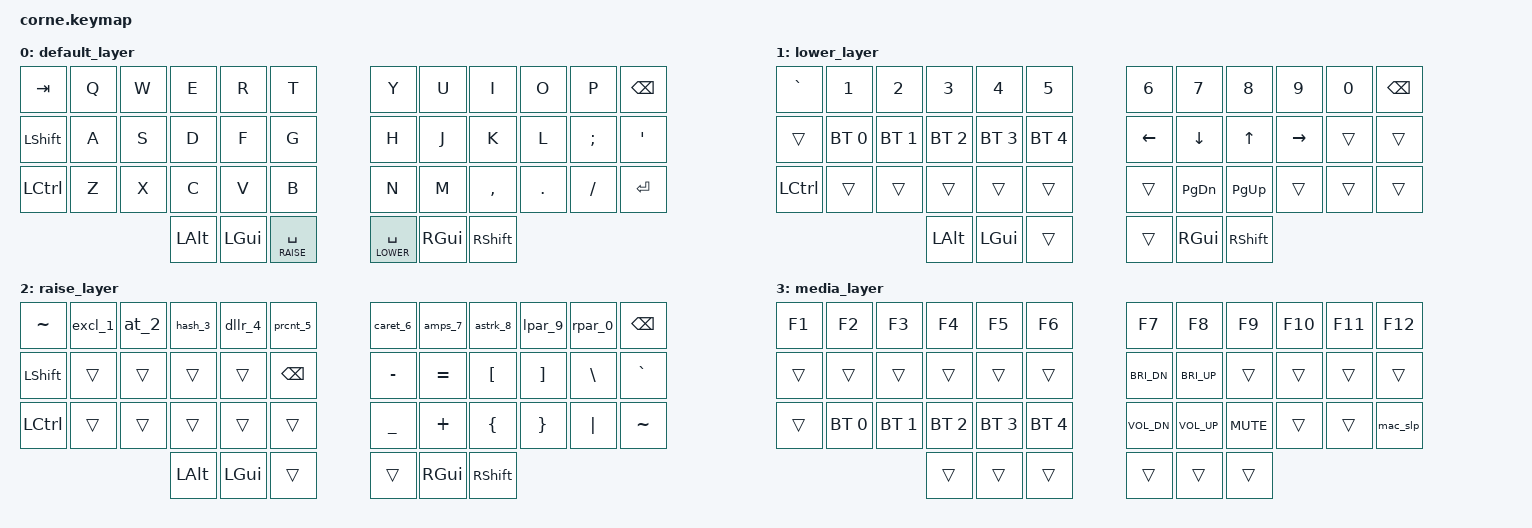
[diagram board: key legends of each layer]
/*
 * Copyright (c) 2020 The ZMK Contributors
 *
 * SPDX-License-Identifier: MIT
 */

#include <behaviors.dtsi>
#include <dt-bindings/zmk/keys.h>
#include <dt-bindings/zmk/bt.h>

// Mapping for different layers
#define DEFAULT 0
#define LOWER   1
#define RAISE   2
#define MEDIA   3


&lt {
    tapping-term-ms = <150>;
};

/ {
    macros {
        mac_slp: mac_slp {
        compatible = "zmk,behavior-macro-two-param";
        #binding-cells = <2>;
        wait-ms = <30>;
        tap-ms = <40>;
        bindings = <&macro_press &kp LCTRL &kp LGUI>
                 , <&macro_tap &kp Q &kp ESC>
                 , <&macro_release &kp LCTRL &kp LGUI>
                 ;
        };
    };
};

/ {
    behaviors {
        excl_1: EXCLAMATION_1 {
            compatible = "zmk,behavior-mod-morph";
            #binding-cells = <0>;
            bindings = <&kp EXCL>, <&kp N1>;
            mods = <(MOD_LSFT|MOD_RSFT)>;
        };
        at_2: AT_2 {
            compatible = "zmk,behavior-mod-morph";
            #binding-cells = <0>;
            bindings = <&kp AT>, <&kp N2>;
            mods = <(MOD_LSFT|MOD_RSFT)>;
        };
        hash_3: HASH_3 {
            compatible = "zmk,behavior-mod-morph";
            #binding-cells = <0>;
            bindings = <&kp HASH>, <&kp N3>;
            mods = <(MOD_LSFT|MOD_RSFT)>;
        };
        dllr_4: DOLLAR_4 {
            compatible = "zmk,behavior-mod-morph";
            #binding-cells = <0>;
            bindings = <&kp DLLR>, <&kp N4>;
            mods = <(MOD_LSFT|MOD_RSFT)>;
        };
        prcnt_5: PERCENT_5 {
            compatible = "zmk,behavior-mod-morph";
            #binding-cells = <0>;
            bindings = <&kp PRCNT>, <&kp N5>;
            mods = <(MOD_LSFT|MOD_RSFT)>;
        };
        caret_6: CARET_6 {
            compatible = "zmk,behavior-mod-morph";
            #binding-cells = <0>;
            bindings = <&kp CARET>, <&kp N6>;
            mods = <(MOD_LSFT|MOD_RSFT)>;
        };
        amps_7: AMPS_7 {
            compatible = "zmk,behavior-mod-morph";
            #binding-cells = <0>;
            bindings = <&kp AMPS>, <&kp N7>;
            mods = <(MOD_LSFT|MOD_RSFT)>;
        };
        astrk_8: ASTRK_7 {
            compatible = "zmk,behavior-mod-morph";
            #binding-cells = <0>;
            bindings = <&kp ASTRK>, <&kp N8>;
            mods = <(MOD_LSFT|MOD_RSFT)>;
        };
        lpar_9: LPAR_9 {
            compatible = "zmk,behavior-mod-morph";
            #binding-cells = <0>;
            bindings = <&kp LPAR>, <&kp N9>;
            mods = <(MOD_LSFT|MOD_RSFT)>;
        };
        rpar_0: RPAR_0 {
            compatible = "zmk,behavior-mod-morph";
            #binding-cells = <0>;
            bindings = <&kp RPAR>, <&kp N0>;
            mods = <(MOD_LSFT|MOD_RSFT)>;
        };
    };
};

/ {
    combos {
        compatible = "zmk,combos";
        combo_esc {
            timeout-ms = <50>;
            key-positions = <0 1>;
            bindings = <&kp ESC>;
        };
        combo_del {
            timeout-ms = <50>;
            key-positions = <10 11>;
            bindings = <&kp DEL>;
        };
        combo_caps {
            timeout-ms = <50>;
            key-positions = <0 1 2>;
            bindings = <&kp CAPS>;
            layers = <0 1 2>;
        };
        combo_media_BT_CLR {
            timeout-ms = <50>;
            key-positions = <0 1 2>;
            bindings = <&bt BT_CLR>;
            layers = <3>;
        };
    };
};

/ {      
    conditional_layers {
        compatible = "zmk,conditional-layers";
        tri_layer {
            if-layers = <1 2>;
            then-layer = <3>;
        };
    };
};


/ {
        keymap {
                compatible = "zmk,keymap";

                default_layer {
// -----------------------------------------------------------------------------------------
// | TAB  |  Q  |  W  |  E  |  R  |  T  |   |  Y  |  U  |  I  |  O  |  P  | BKSP |
// | SHFT |  A  |  S  |  D  |  F  |  G  |   |  H  |  J  |  K  |  L  |  ;  |  '   |
// | CTRL |  Z  |  X  |  C  |  V  |  B  |   |  N  |  M  |  ,  |  .  |  /  | ENT  |
//                    | ALT | GUI | SPC |   | SPC | GUI | SHFT |
                        
                bindings = <
   &kp TAB    &kp Q &kp W &kp E &kp R &kp T              &kp Y &kp U  &kp I     &kp O   &kp P    &kp BKSP
   &kp LSHFT  &kp A &kp S &kp D &kp F &kp G              &kp H &kp J  &kp K     &kp L   &kp SEMI &kp SQT
   &kp LCTRL  &kp Z &kp X &kp C &kp V &kp B              &kp N &kp M  &kp COMMA &kp DOT &kp FSLH &kp RET
                    &kp LALT &kp LGUI &lt RAISE SPACE    &lt LOWER SPACE &kp RGUI &kp RSHFT
                        >;
                };

                lower_layer {
// -----------------------------------------------------------------------------------------
// |   `  |  1  |  2  |  3  |  4  |  5  |   |  6  |  7  |  8  |  9  |  0  | BKSP |
// |      |     |     |     |     |     |   | LFT | DWN |  UP | RGT |     |      |
// | CTRL |     |     |     |     |     |   |     | PG_DN | PG_UP |     |     |      |
//                    | ALT | GUI |     |   |     | GUI | ALT |
                
                bindings = <
   &kp GRAVE  &kp N1       &kp N2       &kp N3       &kp N4       &kp N5         &kp N6   &kp N7      &kp N8    &kp N9    &kp N0 &kp BSPC
   &trans     &bt BT_SEL 0 &bt BT_SEL 1 &bt BT_SEL 2 &bt BT_SEL 3 &bt BT_SEL 4   &kp LEFT &kp DOWN    &kp UP    &kp RIGHT &trans &trans
   &kp LCTRL  &trans       &trans       &trans       &trans       &trans         &trans   &kp PG_DN   &kp PG_UP &trans    &trans &trans
                                        &kp LALT     &kp LGUI     &trans         &trans   &kp RGUI &kp RSHFT
                        >;
                };

                raise_layer {
// -----------------------------------------------------------------------------------------
// |  ~   |  !  |  @  |  #  |  $  |  %  |   |  ^  |  &  |  *  |  (  |  )  | BKSP |
// | SHFT |     |     |     |     |     |   |  -  |  =  |  [  |  ]  |  \  |  `   |
// | CTRL |     |     |     |     |     |   |  _  |  +  |  {  |  }  | "|" |  ~   |
//                    | ALT | GUI |     |   |     | GUI | ALT |
                bindings = <
   &kp TILDE &excl_1  &at_2  &hash_3  &dllr_4  &prcnt_5    &caret_6  &amps_7   &astrk_8  &lpar_9  &rpar_0  &kp BSPC
   &kp LSHFT &trans   &trans &trans   &trans   &kp BSPC    &kp MINUS &kp EQUAL &kp LBKT  &kp RBKT &kp BSLH &kp GRAVE
   &kp LCTRL &trans   &trans &trans   &trans   &trans      &kp UNDER &kp PLUS  &kp LBRC  &kp RBRC &kp PIPE &kp TILDE
                             &kp LALT &kp LGUI &trans      &trans &kp RGUI  &kp RSHFT
                        >;
                };

                media_layer {
// -----------------------------------------------------------------------------------------
// |          |   F1   |   F2  |   F3   |   F4   |   F5   |  |   F6   |    F7   |   F8   |   F9   |   F10  |  F11  | 
// |          |        |       |        |        |        |  | BRI_DN |  BRI_UP |        |        |        |       |
// |  BT_CLR  |   BT1  |   BT2 |  BT3   |   BT4  |  BT5   |  | VOL_DN | VOL_UP  |  MUTE  |        |        |  SLP  |
//                             |        |        |        |  |        |         |        |
                bindings = <
   &kp F1     &kp F2       &kp F3       &kp F4       &kp F5       &kp F6           &kp F7       &kp F8       &kp F9     &kp F10 &kp F11 &kp F12
   &trans     &trans       &trans       &trans       &trans       &trans           &kp C_BRI_DN &kp C_BRI_UP &trans     &trans  &trans  &trans
   &trans     &bt BT_SEL 0 &bt BT_SEL 1 &bt BT_SEL 2 &bt BT_SEL 3 &bt BT_SEL 4     &kp C_VOL_DN &kp C_VOL_UP &kp C_MUTE &trans  &trans  &mac_slp
                                        &trans       &trans       &trans           &trans        &trans       &trans
                        >;
                };
        };
};
